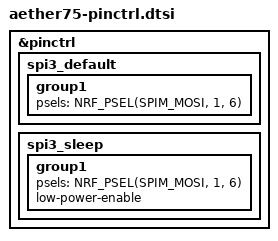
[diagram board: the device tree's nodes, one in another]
/*
 * Copyright (c) 2025 Miguelio
 * SPDX-License-Identifier: MIT
 */

&pinctrl {
    spi3_default: spi3_default {
        group1 {
            psels = <NRF_PSEL(SPIM_MOSI, 1, 6)>;
        };
    };

    spi3_sleep: spi3_sleep {
        group1 {
            psels = <NRF_PSEL(SPIM_MOSI, 1, 6)>;
            low-power-enable;
        };
    };
};
